# ATmega649A device description
Architecture: AVR8; Family: megaAVR
Registers are 8-bit, access not given, no defined reset value unless marked. A register's access mark holds for its fields unless they carry their own. Offsets are from the block's base; [hi:lo] are bit positions; {n}, {i} and the like mark numbered series.

## USART0 — USART
Instances: USART0 0x00
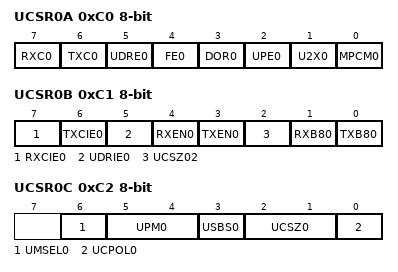
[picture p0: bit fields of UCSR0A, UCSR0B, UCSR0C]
0xC0 UCSR0A — USART Control and Status Register A
  [7] RXC0 — USART Receive Complete
  [6] TXC0 — USART Transmit Complete
  [5] UDRE0 — USART Data Register Empty
  [4] FE0 — Framing Error
  [3] DOR0 — Data OverRun
  [2] UPE0 — USART Parity Error
  [1] U2X0 — Double the USART Transmission Speed
  [0] MPCM0 — Multi-processor Communication Mode
0xC1 UCSR0B — USART Control and Status Register B
  [7] RXCIE0 — RX Complete Interrupt Enable
  [6] TXCIE0 — TX Complete Interrupt Enable
  [5] UDRIE0 — USART Data Register Empty Interrupt Enable
  [4] RXEN0 — Receiver Enable
  [3] TXEN0 — Transmitter Enable
  [2] UCSZ02 — Character Size
  [1] RXB80 — Receive Data Bit 8
  [0] TXB80 — Transmit Data Bit 8
0xC2 UCSR0C — USART Control and Status Register C
  [6] UMSEL0 — USART Mode Select
    0=Asynchronous Operation; 1=Synchronous Operation
  [5:4] UPM0 — Parity Mode Bits
    0=Disabled; 2=Enabled, Even Parity; 3=Enabled, Odd Parity
  [3] USBS0 — Stop Bit Select
    0=1-bit; 1=2-bit
  [2:1] UCSZ0 — Character Size
  [0] UCPOL0 — Clock Polarity
0xC4 UBRR0 16-bit bits used 11:0 — USART Baud Rate Register Bytes
0xC6 UDR0 — USART I/O Data Register

## CPU — CPU Registers
Instances: CPU 0x00
Parameters: CORE_VERSION=V2E
0x3E GPIOR0 — General Purpose IO Register 0
0x4A GPIOR1 — General Purpose IO Register 1
0x4B GPIOR2 — General Purpose IO Register 2
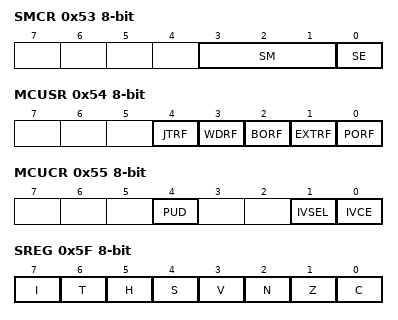
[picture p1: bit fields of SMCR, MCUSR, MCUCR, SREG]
0x53 SMCR — Sleep Mode Control Register
  [3:1] SM — Sleep Mode Select bits
    0=IDLE; 1=ADC (ADC Noise Reduction (If Available)); 2=PDOWN (Power Down); 3=PSAVE (Power Save); 6=STDBY (Standby)
  [0] SE — Sleep Enable
0x54 MCUSR — MCU Status Register
  [4] JTRF — JTAG Reset Flag
  [3] WDRF — Watchdog Reset Flag
  [2] BORF — Brown-out Reset Flag
  [1] EXTRF — External Reset Flag
  [0] PORF — Power-on reset flag
0x55 MCUCR — MCU Control Register
  [4] PUD — Pull-up disable
  [1] IVSEL — Interrupt Vector Select
  [0] IVCE — Interrupt Vector Change Enable
0x5D SP 16-bit — Stack Pointer
0x5F SREG — Status Register
  [7] I — Global Interrupt Enable
  [6] T — Bit Copy Storage
  [5] H — Half Carry Flag
  [4] S — Sign Bit
  [3] V — Two's Complement Overflow Flag
  [2] N — Negative Flag
  [1] Z — Zero Flag
  [0] C — Carry Flag
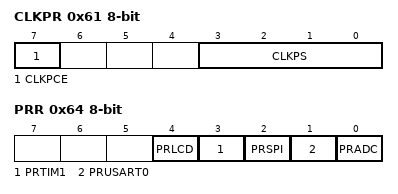
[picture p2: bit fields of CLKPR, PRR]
0x61 CLKPR — Clock Prescale Register
  [7] CLKPCE — Clock Prescaler Change Enable
  [3:0] CLKPS — Clock Prescaler Select Bits
    0=1; 1=2; 2=4; 3=8; 4=16; 5=32; 6=64; 7=128; 8=256
0x64 PRR — Power Reduction Register
  [4] PRLCD — Power Reduction LCD
  [3] PRTIM1 — Power Reduction Timer/Counter1
  [2] PRSPI — Power Reduction Serial Peripheral Interface
  [1] PRUSART0 — Power Reduction USART
  [0] PRADC — Power Reduction ADC
0x66 OSCCAL — Oscillator Calibration Value
  [7:0] OSCCAL — Oscillator Calibration
Value list OSCCAL_VALUE_ADDRESSES: 0=8_0_MHz

## JTAG — JTAG Interface
Instances: JTAG 0x00
0x51 OCDR — On-Chip Debug Related Register in I/O Memory
0x54 MCUSR — MCU Status Register
  [4] JTRF — JTAG Reset Flag
0x55 MCUCR — MCU Control Register
  [7] JTD — JTAG Interface Disable

## LCD — Liquid Crystal Display
Instances: LCD 0x00
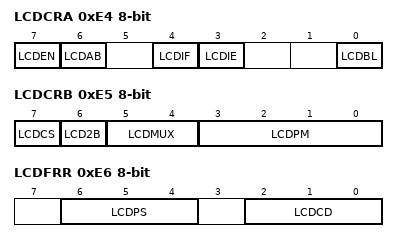
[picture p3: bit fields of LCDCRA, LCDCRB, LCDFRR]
0xE4 LCDCRA — LCD Control Register A
  [7] LCDEN — LCD Enable
  [6] LCDAB — LCD A or B waveform
  [4] LCDIF — LCD Interrupt Flag
  [3] LCDIE — LCD Interrupt Enable
  [0] LCDBL — LCD Blanking
0xE5 LCDCRB — LCD Control and Status Register B
  [7] LCDCS — LCD CLock Select
  [6] LCD2B — LCD 1/2 Bias Select
  [5:4] LCDMUX — LCD Mux Selects
  [3:0] LCDPM — LCD Port Masks
    0=SEG0:12; 1=SEG0:14; 2=SEG0:15; 3=SEG0:18; 4=SEG0:20; 5=SEG0:22; 6=SEG0:23; 7=SEG0:24; 8=SEG0:26; 9=SEG0:28; 10=SEG0:30; 11=SEG0:32; 12=SEG0:34; 13=SEG0:36; 14=SEG0:38; 15=SEG0:39
0xE6 LCDFRR — LCD Frame Rate Register
  [6:4] LCDPS — LCD Prescaler Selects
    0=ClkLCD/16; 1=ClkLCD/64; 2=ClkLCD/128; 3=ClkLCD/256; 4=ClkLCD/512; 5=ClkLCD/1024; 6=ClkLCD/2048; 7=ClkLCD/4096
  [2:0] LCDCD — LCD Clock Dividers
    {v}={v+1} (v=0..7)
0xE7 LCDCCR bits used 7:5,3:0 — LCD Contrast Control Register
{0xEC+i} LCDDR{i} (i=0..2) — LCD Data Register {i}
0xEF LCDDR3 bits used 0 — LCD Data Register 3
{0xEC+i} LCDDR{i} (i=5..7) — LCD Data Register {i}
0xF4 LCDDR8 bits used 0 — LCD Data Register 8
{0xEC+i} LCDDR{i} (i=10..12) — LCD Data Register {i}
0xF9 LCDDR13 bits used 0 — LCD Data Register 13
{0xEC+i} LCDDR{i} (i=15..17) — LCD Data Register {i}
0xFE LCDDR18 bits used 0 — LCD Data Register 18
